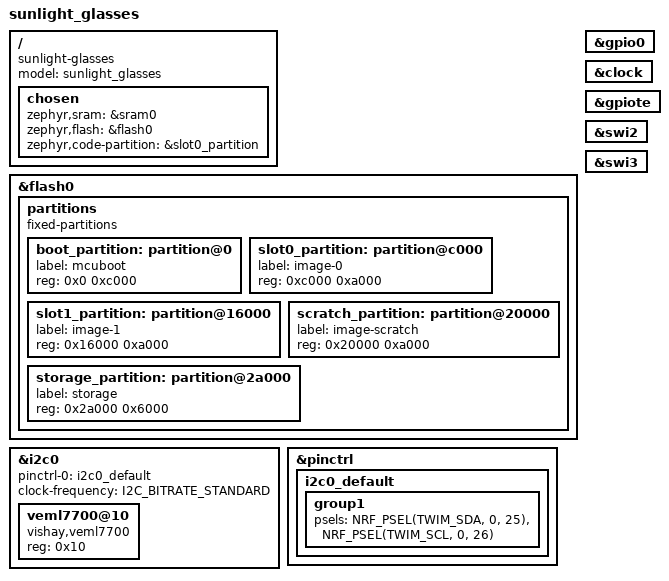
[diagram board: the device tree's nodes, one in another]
// Copyright (c) 2024 Nordic Semiconductor ASA
// SPDX-License-Identifier: Apache-2.0

/dts-v1/;
#include <nordic/nrf52810_qfaa.dtsi>

/ {
	model = "sunlight_glasses";
	compatible = "sunlight-glasses";

	chosen {
		zephyr,sram = &sram0;
		zephyr,flash = &flash0;
		zephyr,code-partition = &slot0_partition;
	};
};

&flash0 {
	partitions {
		compatible = "fixed-partitions";
		#address-cells = <1>;
		#size-cells = <1>;

		boot_partition: partition@0 {
			label = "mcuboot";
			reg = <0x0 0xc000>;
		};
		slot0_partition: partition@c000 {
			label = "image-0";
			reg = <0xc000 0xa000>;
		};
		slot1_partition: partition@16000 {
			label = "image-1";
			reg = <0x16000 0xa000>;
		};
		scratch_partition: partition@20000 {
			label = "image-scratch";
			reg = <0x20000 0xa000>;
		};
		storage_partition: partition@2a000 {
			label = "storage";
			reg = <0x2a000 0x6000>;
		};
	};
};





&i2c0 {
	status = "okay";
	pinctrl-0 = <&i2c0_default>;
	pinctrl-names = "default";
	clock-frequency = <I2C_BITRATE_STANDARD>;
	veml7700@10 {
		compatible = "vishay,veml7700";
		reg = <0x10>; //this is the i2c address
	};
};

&gpio0 {
	status = "okay";
};

&pinctrl {
	i2c0_default: i2c0_default {
		group1 {
			psels = <NRF_PSEL(TWIM_SDA, 0, 25)>, <NRF_PSEL(TWIM_SCL, 0, 26)>;
		};
	};
};

&clock {
	status = "okay";
};

&gpiote {
	status = "okay";
};

&swi2 {
	status = "okay";
};

&swi3 {
	status = "okay";
};
